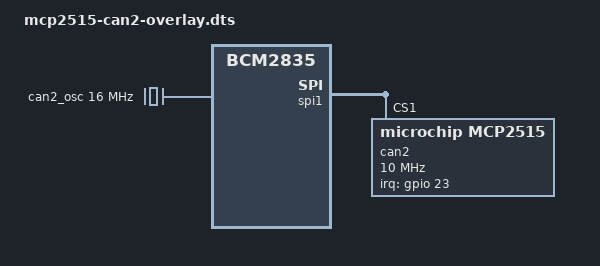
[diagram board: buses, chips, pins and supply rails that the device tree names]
/dts-v1/;
/plugin/;

/ {
    compatible = "brcm,bcm2835";

    fragment@0 {
        target = <&spi1>;
        __overlay__ {
            status = "okay";
        };
    };

    fragment@1 {
        target = <&gpio>;
        __overlay__ {
            can2_pins: can2_pins {
                brcm,pins = <23>;
                brcm,function = <0>; /* input */
            };
        };
    };

    fragment@2 {
        target-path = "/";
        __overlay__ {
            can2_osc: can2_osc {
                compatible = "fixed-clock";
                #clock-cells = <0>;
                clock-frequency = <16000000>;
            };
        };
    };

    fragment@3 {
        target = <&spi1>;
        __overlay__ {
            #address-cells = <1>;
            #size-cells = <0>;
            can2: mcp2515@1 {
                reg = <1>; /* CS1 on SPI1 */
                compatible = "microchip,mcp2515";
                pinctrl-names = "default";
                pinctrl-0 = <&can2_pins>;
                spi-max-frequency = <10000000>;
                interrupt-parent = <&gpio>;
                interrupts = <23 0>; /* GPIO23, IRQ_TYPE_LEVEL_LOW */
                clocks = <&can2_osc>;
            };
        };
    };

    __overrides__ {
        oscillator = <&can2_osc>,"clock-frequency:0";
        spimaxfrequency = <&can2>,"spi-max-frequency:0";
        interrupt = <&can2_pins>,"brcm,pins:0",<&can2>,"interrupts:0";
    };
};
